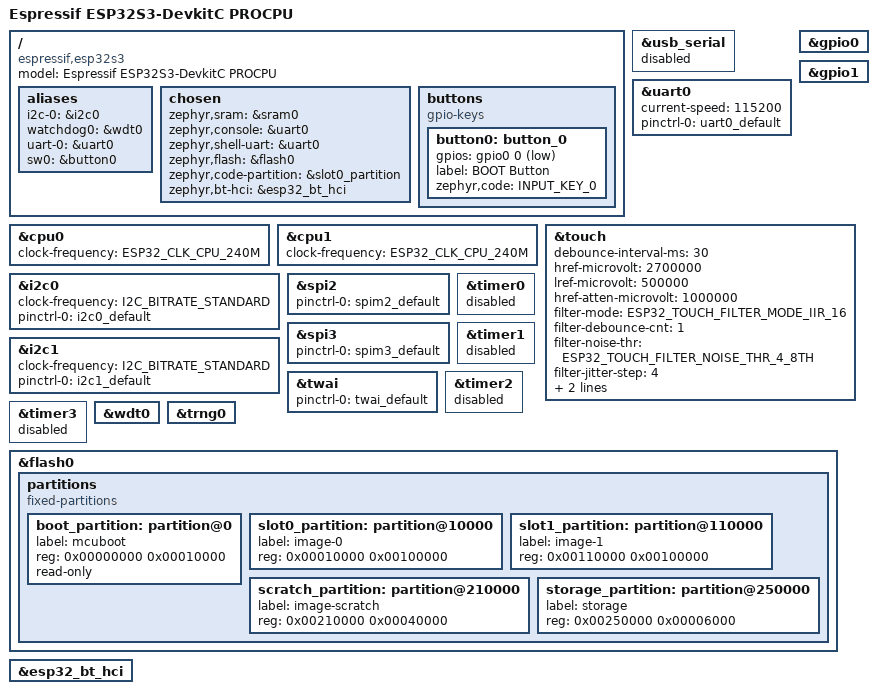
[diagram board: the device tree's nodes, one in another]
/*
 * Copyright (c) 2024 Espressif Systems (Shanghai) Co., Ltd.
 *
 * SPDX-License-Identifier: Apache-2.0
 */
/dts-v1/;

#include "espressif/esp32s3/esp32s3_wroom_n8.dtsi"
#include "esp32s3_devkitc-pinctrl.dtsi"
#include <zephyr/dt-bindings/input/input-event-codes.h>
#include <zephyr/dt-bindings/input/esp32-touch-sensor-input.h>

/ {
	model = "Espressif ESP32S3-DevkitC PROCPU";
	compatible = "espressif,esp32s3";

	aliases {
		i2c-0 = &i2c0;
		watchdog0 = &wdt0;
	};

	chosen {
		zephyr,sram = &sram0;
		zephyr,console = &uart0;
		zephyr,shell-uart = &uart0;
		zephyr,flash = &flash0;
		zephyr,code-partition = &slot0_partition;
		zephyr,bt-hci = &esp32_bt_hci;
	};

	aliases {
		uart-0 = &uart0;
		sw0 = &button0;
	};

	buttons {
		compatible = "gpio-keys";
		button0: button_0 {
			gpios = <&gpio0 0 (GPIO_PULL_UP | GPIO_ACTIVE_LOW)>;
			label = "BOOT Button";
			zephyr,code = <INPUT_KEY_0>;
		};
	};
};

&cpu0 {
	clock-frequency = <ESP32_CLK_CPU_240M>;
};

&cpu1 {
	clock-frequency = <ESP32_CLK_CPU_240M>;
};

&usb_serial {
	status = "disabled";
};

&uart0 {
	status = "okay";
	current-speed = <115200>;
	pinctrl-0 = <&uart0_default>;
	pinctrl-names = "default";
};

&gpio0 {
	status = "okay";
};

&gpio1 {
	status = "okay";
};

&touch {
	debounce-interval-ms = <30>;
	href-microvolt = <2700000>;
	lref-microvolt = <500000>;
	href-atten-microvolt = <1000000>;
	filter-mode = <ESP32_TOUCH_FILTER_MODE_IIR_16>;
	filter-debounce-cnt = <1>;
	filter-noise-thr = <ESP32_TOUCH_FILTER_NOISE_THR_4_8TH>;
	filter-jitter-step = <4>;
	filter-smooth-level = <ESP32_TOUCH_FILTER_SMOOTH_MODE_IIR_2>;
};

&i2c0 {
	clock-frequency = <I2C_BITRATE_STANDARD>;
	pinctrl-0 = <&i2c0_default>;
	pinctrl-names = "default";
};

&i2c1 {
	clock-frequency = <I2C_BITRATE_STANDARD>;
	pinctrl-0 = <&i2c1_default>;
	pinctrl-names = "default";
};

&spi2 {
	#address-cells = <1>;
	#size-cells = <0>;
	status = "okay";
	pinctrl-0 = <&spim2_default>;
	pinctrl-names = "default";
};

&spi3 {
	#address-cells = <1>;
	#size-cells = <0>;
	status = "okay";
	pinctrl-0 = <&spim3_default>;
	pinctrl-names = "default";
};

&twai {
	pinctrl-0 = <&twai_default>;
	pinctrl-names = "default";
};

&timer0 {
	status = "disabled";
};

&timer1 {
	status = "disabled";
};

&timer2 {
	status = "disabled";
};

&timer3 {
	status = "disabled";
};

&wdt0 {
	status = "okay";
};

&trng0 {
	status = "okay";
};

&flash0 {
	status = "okay";
	partitions {
		compatible = "fixed-partitions";
		#address-cells = <1>;
		#size-cells = <1>;

		/* Reserve 64kB for the bootloader */
		boot_partition: partition@0 {
			label = "mcuboot";
			reg = <0x00000000 0x00010000>;
			read-only;
		};

		/* Reserve 1024kB for the application in slot 0 */
		slot0_partition: partition@10000 {
			label = "image-0";
			reg = <0x00010000 0x00100000>;
		};

		/* Reserve 1024kB for the application in slot 1 */
		slot1_partition: partition@110000 {
			label = "image-1";
			reg = <0x00110000 0x00100000>;
		};

		/* Reserve 256kB for the scratch partition */
		scratch_partition: partition@210000 {
			   label = "image-scratch";
			   reg = <0x00210000 0x00040000>;
		};

		storage_partition: partition@250000 {
			label = "storage";
			reg = <0x00250000 0x00006000>;
		};
	};
};

&esp32_bt_hci {
	status = "okay";
};
